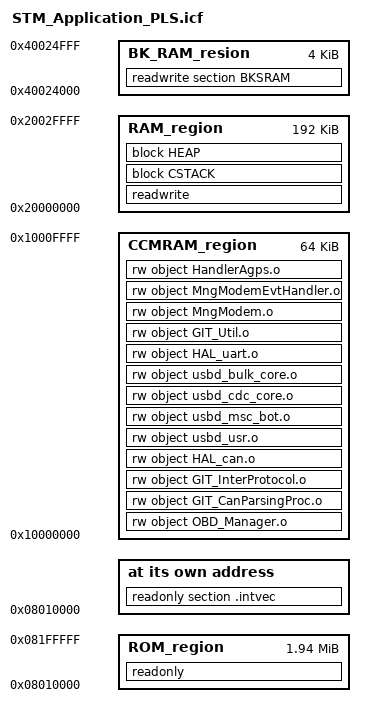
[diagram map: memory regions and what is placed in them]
/*###ICF### Section handled by ICF editor, don't touch! ****/
/*-Editor annotation file-*/
/* IcfEditorFile="$TOOLKIT_DIR$\config\ide\IcfEditor\cortex_v1_0.xml" */
/*-Specials-*/
define symbol __ICFEDIT_intvec_start__ = 0x08010000;
/*-Memory Regions-*/
define symbol __ICFEDIT_region_ROM_start__    = 0x08010000;
define symbol __ICFEDIT_region_ROM_end__      = 0x081FFFFF;
define symbol __ICFEDIT_region_RAM_start__    = 0x20000000;
define symbol __ICFEDIT_region_RAM_end__      = 0x2002FFFF;
define symbol __ICFEDIT_region_CCMRAM_start__ = 0x10000000;
define symbol __ICFEDIT_region_CCMRAM_end__   = 0x1000FFFF;
/*-Sizes-*/
define symbol __ICFEDIT_size_cstack__ = 0xA000;
define symbol __ICFEDIT_size_heap__   = 0xA400;
/**** End of ICF editor section. ###ICF###*/


define memory mem with size = 4G;
define region ROM_region   = mem:[from __ICFEDIT_region_ROM_start__   to __ICFEDIT_region_ROM_end__];
define region RAM_region   = mem:[from __ICFEDIT_region_RAM_start__   to __ICFEDIT_region_RAM_end__];
define region CCMRAM_region   = mem:[from __ICFEDIT_region_CCMRAM_start__   to __ICFEDIT_region_CCMRAM_end__];

define symbol __BK_RAM_start__ = 0x40024000;
define symbol __BK_RAM_end__   = 0x40024FFF;
define region BK_RAM_resion = mem:[from __BK_RAM_start__   to __BK_RAM_end__];

define block CSTACK    with alignment = 8, size = __ICFEDIT_size_cstack__   { };
define block HEAP      with alignment = 8, size = __ICFEDIT_size_heap__     { };

initialize by copy { readwrite };
do not initialize  { section .noinit };

place at address mem:__ICFEDIT_intvec_start__ { readonly section .intvec };

place in ROM_region   { readonly};
place in RAM_region   { readwrite, block CSTACK, block HEAP };
place in BK_RAM_resion   { readwrite section BKSRAM };

place in CCMRAM_region   { rw object OBD_Manager.o, rw object GIT_CanParsingProc.o, rw object GIT_InterProtocol.o, rw object HAL_can.o, rw object usbd_usr.o, rw object usbd_msc_bot.o, rw object usbd_cdc_core.o, rw object usbd_bulk_core.o, rw object HAL_uart.o, rw object GIT_Util.o, rw object MngModem.o, rw object MngModemEvtHandler.o, rw object HandlerAgps.o};
/*place in CCMRAM_region   { rw object OBD_Manager.o};*/
/*place in CCMRAM_region   { rw object GIT_CanParsingProc.o, rw object GIT_InterProtocol.o, rw object app_cli.o, rw object can.o, rw object uart.o, rw object GIT_Util.o};*/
